# AC7842x register map
Vendor: AutoChips; Series: AC78; File version: 1.0
CPU: CM4 r0p1, little endian, MPU, FPU, VTOR, 4 interrupt priority bits
Registers are 32-bit, read-write, reset 0x0 unless marked. A register's access mark holds for its fields unless they carry their own. Offsets are from the block's base; [hi:lo] are bit positions.

## I2C0 — Inter-Integrated Circuit
Base 0x4000E000
Same registers: I2C1 0x4000E800
0x00 ADDR0 reset 0xFE — Address Register 0
  [7:1] AD — 7Bit Address
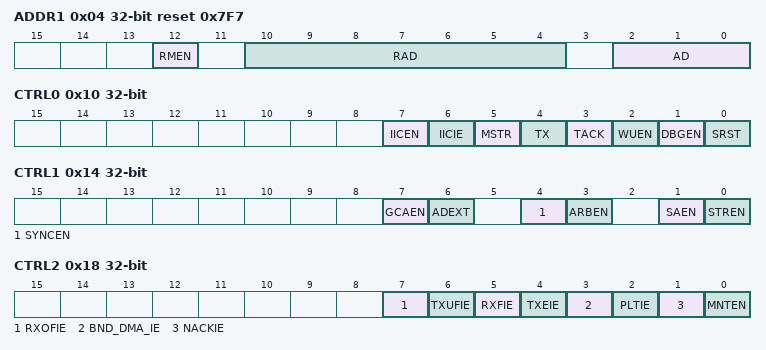
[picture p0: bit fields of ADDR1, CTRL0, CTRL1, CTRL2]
0x04 ADDR1 reset 0x7F7 — Address register 1
  [12] RMEN — 7bit Range Enable
    0=Disable 7bit range address; 1=Enable 7bit range address
  [10:4] RAD — 7bit Range Address
  [2:0] AD — 10Bit Address
0x08 SAMPLE_CNT reset 0x4
  [7:0] DIV — Adjust the width of each sample
0x0C STEP_CNT reset 0x4
  [7:0] DIV — Specifies the number of Samples per half pulse width
0x10 CTRL0 — Control Register 0
  [7] IICEN — I2C Module Enable
    0=Disable; 1=Enable
  [6] IICIE — I2C interrupt Enable
    0=Disable; 1=Enable
  [5] MSTR — I2C operation mode Select
    0=Slave Mode; 1=Master Mode
  [4] TX — Master Transmit Direction Select
    0=Receive(RX); 1=Transmit(TX)
  [3] TACK — Transmit Acknowledge Enable
    0=ACK will sent to the bus on the following receiving byte; 1=NACK will sent to the bus on the following receiving byte
  [2] WUEN — wakeup enable
    0=Disable the wakeup function; 1=Enable the wakeup function in low power mode
  [1] DBGEN — Debug Enable
    0=Master is disabled in debug mode; 1=Master is enabled in debug mode
  [0] SRST — Software reset of master and slave
    0=Master and slave logic is not reset; 1=Master and slave logic is reset
0x14 CTRL1 — Control Register 1
  [7] GCAEN — Slave General Call Enable
    0=Slave general call is disabled; 1=Slave general call is enabled
  [6] ADEXT — Slave Address Extension
    0=7-bit address scheme; 1=10-bit address scheme
  [4] SYNCEN — Master SCL Sync Enable
    0=Master SCL sync is disabled; 1=Master SCL sync is enabled
  [3] ARBEN — Master Arbitration Enable
    0=Master arbitration is disabled; 1=Master arbitration is enabled
  [1] SAEN — SMBus Alert Enable
    0=SMBus Alert is disabled; 1=SMBus Alert is enabled
  [0] STREN — Slave SCL Stretch Enable
    0=Slave SCL stretch is disabled; 1=Slave SCL stretch is enabled
0x18 CTRL2 — Control Register 2
  [7] RXOFIE — Slave RX Buffer Overflow Error Interrupt Enable
    0=Slave RX buffer overflow error interrupt is disabled; 1=Slave RX buffer overflow error interrupt is enabled
  [6] TXUFIE — Slave TX Buffer Underflow Error Interrupt Enable
    0=Slave TX buffer underflow error interrupt is disabled; 1=Slave TX buffer underflow error interrupt is enabled
  [5] RXFIE — Slave RX Buffer Full Interrupt Enable
    0=Slave RX buffer full interrupt is disabled; 1=Slave RX buffer full interrupt is enabled
  [4] TXEIE — Slave TX Buffer Empty Interrupt Enable
    0=Slave TX buffer empty interrupt is disabled; 1=Slave TX buffer empty interrupt is enabled
  [3] BND_DMA_IE — Byte end after DMA finish Interrupt Enable
    0=Byte end after DMA finish interrupt is disabled; 1=Byte end after DMA finish interrupt is enabled
  [2] PLTIE — Pin Low Timeout Interrupt Enable
    0=Pin low timeout interrupt is disabled; 1=Pin low timeout interrupt is enabled
  [1] NACKIE — NACK Get Interrupt Enable
    0=NACK get interrupt is disabled; 1=NACK get interrupt is enabled
  [0] MNTEN — Slave Monitor Function Enable
    0=Slave monitor function is disabled; 1=Slave monitor function is enabled
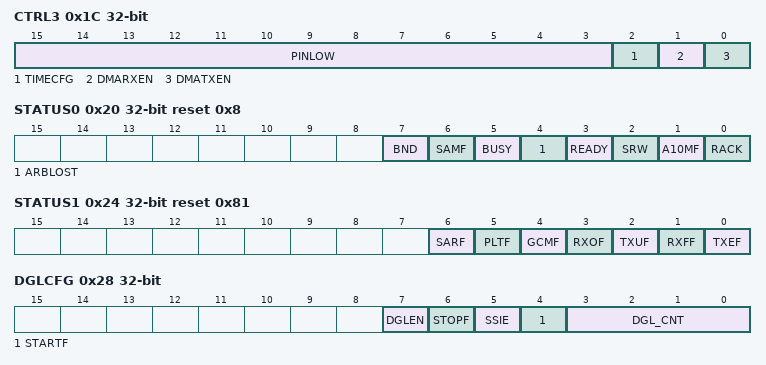
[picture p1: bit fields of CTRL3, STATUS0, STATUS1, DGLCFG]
0x1C CTRL3 — Control Register 3
  [15:3] PINLOW — PIN LOW Timeout
  [2] TIMECFG — Timeout Configuration
    0=SCL is low for longer than the configured timeout; 1=SCL or SDA is low for longer than the configured timeout
  [1] DMARXEN — DMARX Enable
    0=DMARX is disabled; 1=DMARX is enabled
  [0] DMATXEN — DMATX Enable
    0=DMATX is disabled; 1=DMATX is enabled
0x20 STATUS0 reset 0x8 — Status Register 0
  [7] BND — Byte Tx End Flag(include ACK bit, 9 SCL)
    0=Transfer in progress, one byte transfer is not finished; 1=One byte transfer is finished
  [6] SAMF — Slave Address Match Flag
    0=Slave address not match; 1=Slave address match
  [5] BUSY ro — Indicates The Status of The Bus in Slave/Master
    0=Bus is idle; 1=Bus is busy
  [4] ARBLOST — Arbitration Lost Flag
    0=Arbitration not lost; 1=Arbitration lost
  [3] READY ro — Internal Hardware Core Is Ready For New Command or Not
    0=Internal hardware is not ready; 1=Internal hardware is ready
  [2] SRW ro — Slave Read/Write Direction
    0=Slave is receiver; 1=Slave is transmitter
  [1] A10MF ro — 10bit address match flag
    0=10bit address not match; 1=10bit address match
  [0] RACK — Acknowledge Received(master or slave TX mode)
    0=Ack signal was received; 1=No Ack signal detected
0x24 STATUS1 reset 0x81 — Status Register 1
  [6] SARF — SMBus Alert Response Flag
    0=SMBus Alert Response is not detected; 1=SMBus Alert Response is detected
  [5] PLTF — Pin Low Timeout Flag
    0=Pin low timeout has not occurred; 1=Pin low timeout has occurred
  [4] GCMF — General Call Match Flag
    0=General call not match; 1=General call match
  [3] RXOF — Slave RX Buffer Overflow Flag
    0=Slave RX buffer not overflow; 1=Slave RX buffer overflow
  [2] TXUF — Slave TX Buffer Underflow Flag
    0=Slave TX buffer not underflow; 1=Slave TX buffer underflow
  [1] RXFF — Slave RX Buffer Full flag
    0=Slave RX buffer not full; 1=Slave RX buffer full
  [0] TXEF — Slave TX Buffer Empty Flag
    0=Slave TX buffer not empty; 1=Slave TX buffer empty
0x28 DGLCFG — Deglitch Configuration Register
  [7] DGLEN — I2C Deglitch Filter Enable
    0=Deglitch filter is disabled; 1=Deglitch filter is enabled
  [6] STOPF — I2C Bus Stop Flag
    0=Stop signal is not detected; 1=Stop signal is detected
  [5] SSIE — I2C Bus START or STOP Interrupt Enable
    0=START or STOP interrupt is disabled; 1=START or STOP interrupt is enabled
  [4] STARTF — I2C Bus Start Flag
    0=Start signal is not detected; 1=Start signal is detected
  [3:0] DGL_CNT — Deglitch Counter
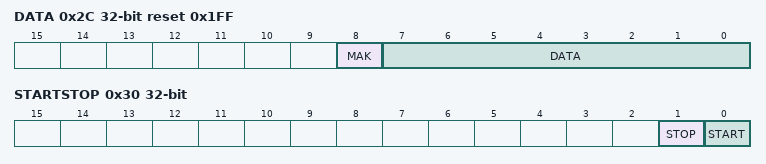
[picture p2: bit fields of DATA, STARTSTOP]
0x2C DATA reset 0x1FF
  [8] MAK ro — Slave Monitor Function ACK bit
    0=Monitor ACK; 1=Monitor NACK
  [7:0] DATA
0x30 STARTSTOP
  [1] STOP — Matsre Send I2C Stop Signal
  [0] START — Master Send Start Signal
